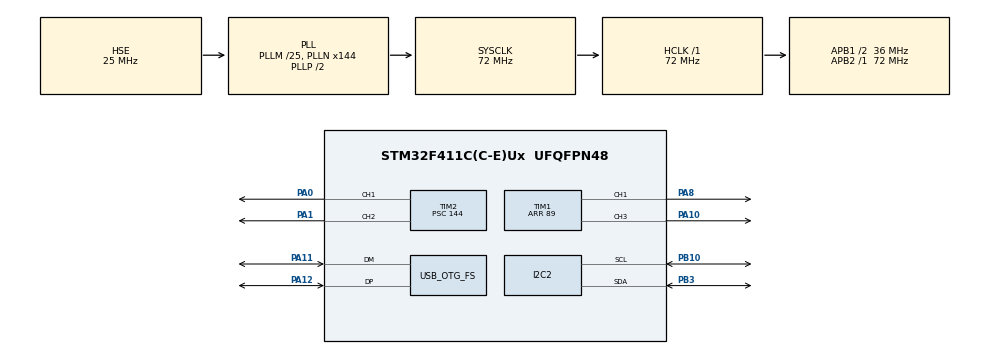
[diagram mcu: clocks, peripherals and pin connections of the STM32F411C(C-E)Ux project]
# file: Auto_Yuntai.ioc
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Dma.Request0=TIM1_CH3
Dma.TIM1_CH3.0.Direction=DMA_MEMORY_TO_PERIPH
Dma.TIM1_CH3.0.FIFOMode=DMA_FIFOMODE_DISABLE
Dma.TIM1_CH3.0.Instance=DMA2_Stream6
Dma.TIM1_CH3.0.MemDataAlignment=DMA_MDATAALIGN_HALFWORD
Dma.TIM1_CH3.0.MemInc=DMA_MINC_ENABLE
Dma.TIM1_CH3.0.Mode=DMA_NORMAL
Dma.TIM1_CH3.0.PeriphDataAlignment=DMA_PDATAALIGN_HALFWORD
Dma.TIM1_CH3.0.PeriphInc=DMA_PINC_DISABLE
Dma.TIM1_CH3.0.Priority=DMA_PRIORITY_LOW
I2C2.I2C_Mode=I2C_Fast
Mcu.Family=STM32F4
Mcu.Name=STM32F411C(C-E)Ux
Mcu.Package=UFQFPN48
NVIC.DMA2_Stream6_IRQn=true\:0\:0\:false\:false\:true\:false\:true
NVIC.OTG_FS_IRQn=true\:0\:0\:false\:false\:true\:false\:true
NVIC.PriorityGroup=NVIC_PRIORITYGROUP_4
PA0-WKUP.Signal=S_TIM2_CH1_ETR
PA1.Signal=S_TIM2_CH2
PA10.Signal=S_TIM1_CH3
PA11.Mode=Device_Only
PA11.Signal=USB_OTG_FS_DM
PA12.Mode=Device_Only
PA12.Signal=USB_OTG_FS_DP
PA13.Mode=Serial_Wire
PA13.Signal=SYS_JTMS-SWDIO
PA14.Mode=Serial_Wire
PA14.Signal=SYS_JTCK-SWCLK
PA8.Signal=S_TIM1_CH1
PB10.Mode=I2C
PB10.Signal=I2C2_SCL
PB3.Mode=I2C
PB3.Signal=I2C2_SDA
PH0\ -\ OSC_IN.Mode=HSE-External-Oscillator
PH0\ -\ OSC_IN.Signal=RCC_OSC_IN
PH1\ -\ OSC_OUT.Mode=HSE-External-Oscillator
PH1\ -\ OSC_OUT.Signal=RCC_OSC_OUT
ProjectManager.HeapSize=0x2000
ProjectManager.StackSize=0x2000
ProjectManager.TargetToolchain=MDK-ARM V5.27
RCC.48MHZClocksFreq_Value=48000000
RCC.AHBFreq_Value=72000000
RCC.APB1CLKDivider=RCC_HCLK_DIV2
RCC.APB1Freq_Value=36000000
RCC.APB1TimFreq_Value=72000000
RCC.APB2Freq_Value=72000000
RCC.APB2TimFreq_Value=72000000
RCC.CortexFreq_Value=72000000
RCC.HCLKFreq_Value=72000000
RCC.HSE_VALUE=25000000
RCC.HSI_VALUE=16000000
RCC.LSE_VALUE=32768
RCC.PLLM=25
RCC.PLLN=144
RCC.PLLQ=3
RCC.SYSCLKFreq_VALUE=72000000
RCC.SYSCLKSource=RCC_SYSCLKSOURCE_PLLCLK
RCC.VCOOutputFreq_Value=144000000
SH.S_TIM1_CH1.0=TIM1_CH1,Forced Output1 CH1
SH.S_TIM1_CH3.0=TIM1_CH3,PWM Generation3 CH3
SH.S_TIM2_CH1_ETR.0=TIM2_CH1,PWM Generation1 CH1
SH.S_TIM2_CH2.0=TIM2_CH2,PWM Generation2 CH2
TIM1.Channel-Forced\ Output1\ CH1=TIM_CHANNEL_1
TIM1.Channel-PWM\ Generation3\ CH3=TIM_CHANNEL_3
TIM1.Period=89
TIM2.Channel-PWM\ Generation1\ CH1=TIM_CHANNEL_1
TIM2.Channel-PWM\ Generation2\ CH2=TIM_CHANNEL_2
TIM2.Period=9999
TIM2.Prescaler=144
USB_DEVICE.CLASS_NAME_FS=CDC
USB_DEVICE.VirtualMode=Cdc
USB_DEVICE.VirtualModeFS=Cdc_FS
USB_OTG_FS.VirtualMode=Device_Only
VP_TIM1_VS_ClockSourceINT.Mode=Internal
VP_TIM2_VS_ClockSourceINT.Mode=Internal
VP_USB_DEVICE_VS_USB_DEVICE_CDC_FS.Mode=CDC_FS
board=custom

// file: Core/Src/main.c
/* USER CODE BEGIN Header */
/**
 ******************************************************************************
 * @file           : main.c
 * @brief          : Main program body
 ******************************************************************************
 * @attention
 *
 * <h2><center>&copy; Copyright (c) 2021 STMicroelectronics.
 * All rights reserved.</center></h2>
 *
 * This software component is licensed by ST under Ultimate Liberty license
 * SLA0044, the "License"; You may not use this file except in compliance with
 * the License. You may obtain a copy of the License at:
 *                             www.st.com/SLA0044
 *
 ******************************************************************************
 */
/* USER CODE END Header */
#include "main.h"
#include "dma.h"
#include "i2c.h"
#include "tim.h"
#include "usb_device.h"
#include "gpio.h"

/* USER CODE BEGIN Includes */
#include "rtthread.h"
#include "user_code.h"
/* USER CODE END Includes */

/* USER CODE BEGIN PV */
static uint8_t system_memory[0x8000] = {0};
/* USER CODE END PV */

void SystemClock_Config(void);

int main(void)
{

  /* MCU Configuration--------------------------------------------------------*/

  /* Reset of all peripherals, Initializes the Flash interface and the Systick. */
  HAL_Init();

  /* Configure the system clock */
  SystemClock_Config();

  /* Initialize all configured peripherals */
  MX_GPIO_Init();
  MX_DMA_Init();
  MX_I2C2_Init();
  MX_TIM2_Init();
  MX_USB_DEVICE_Init();
  MX_TIM1_Init();
  /* USER CODE BEGIN 2 */
    rt_system_heap_init((void*)system_memory, (void*)(system_memory + sizeof(system_memory)));
    rt_system_timer_init();
    rt_system_scheduler_init();
    rt_thread_idle_init();
    user_code();
  /* USER CODE END 2 */

  /* Infinite loop */
    while (1)
    {

    }
}

void SystemClock_Config(void)
{
  RCC_OscInitTypeDef RCC_OscInitStruct = {0};
  RCC_ClkInitTypeDef RCC_ClkInitStruct = {0};

  /** Configure the main internal regulator output voltage
  */
  __HAL_RCC_PWR_CLK_ENABLE();
  __HAL_PWR_VOLTAGESCALING_CONFIG(PWR_REGULATOR_VOLTAGE_SCALE1);
  /** Initializes the RCC Oscillators according to the specified parameters
  * in the RCC_OscInitTypeDef structure.
  */
  RCC_OscInitStruct.OscillatorType = RCC_OSCILLATORTYPE_HSE;
  RCC_OscInitStruct.HSEState = RCC_HSE_ON;
  RCC_OscInitStruct.PLL.PLLState = RCC_PLL_ON;
  RCC_OscInitStruct.PLL.PLLSource = RCC_PLLSOURCE_HSE;
  RCC_OscInitStruct.PLL.PLLM = 25;
  RCC_OscInitStruct.PLL.PLLN = 144;
  RCC_OscInitStruct.PLL.PLLP = RCC_PLLP_DIV2;
  RCC_OscInitStruct.PLL.PLLQ = 3;
  if (HAL_RCC_OscConfig(&RCC_OscInitStruct) != HAL_OK)
  {
    Error_Handler();
  }
  /** Initializes the CPU, AHB and APB buses clocks
  */
  RCC_ClkInitStruct.ClockType = RCC_CLOCKTYPE_HCLK|RCC_CLOCKTYPE_SYSCLK
                              |RCC_CLOCKTYPE_PCLK1|RCC_CLOCKTYPE_PCLK2;
  RCC_ClkInitStruct.SYSCLKSource = RCC_SYSCLKSOURCE_PLLCLK;
  RCC_ClkInitStruct.AHBCLKDivider = RCC_SYSCLK_DIV1;
  RCC_ClkInitStruct.APB1CLKDivider = RCC_HCLK_DIV2;
  RCC_ClkInitStruct.APB2CLKDivider = RCC_HCLK_DIV1;

  if (HAL_RCC_ClockConfig(&RCC_ClkInitStruct, FLASH_LATENCY_2) != HAL_OK)
  {
    Error_Handler();
  }
}

void Error_Handler(void)
{
}

/************************ (C) COPYRIGHT STMicroelectronics *****END OF FILE****/
